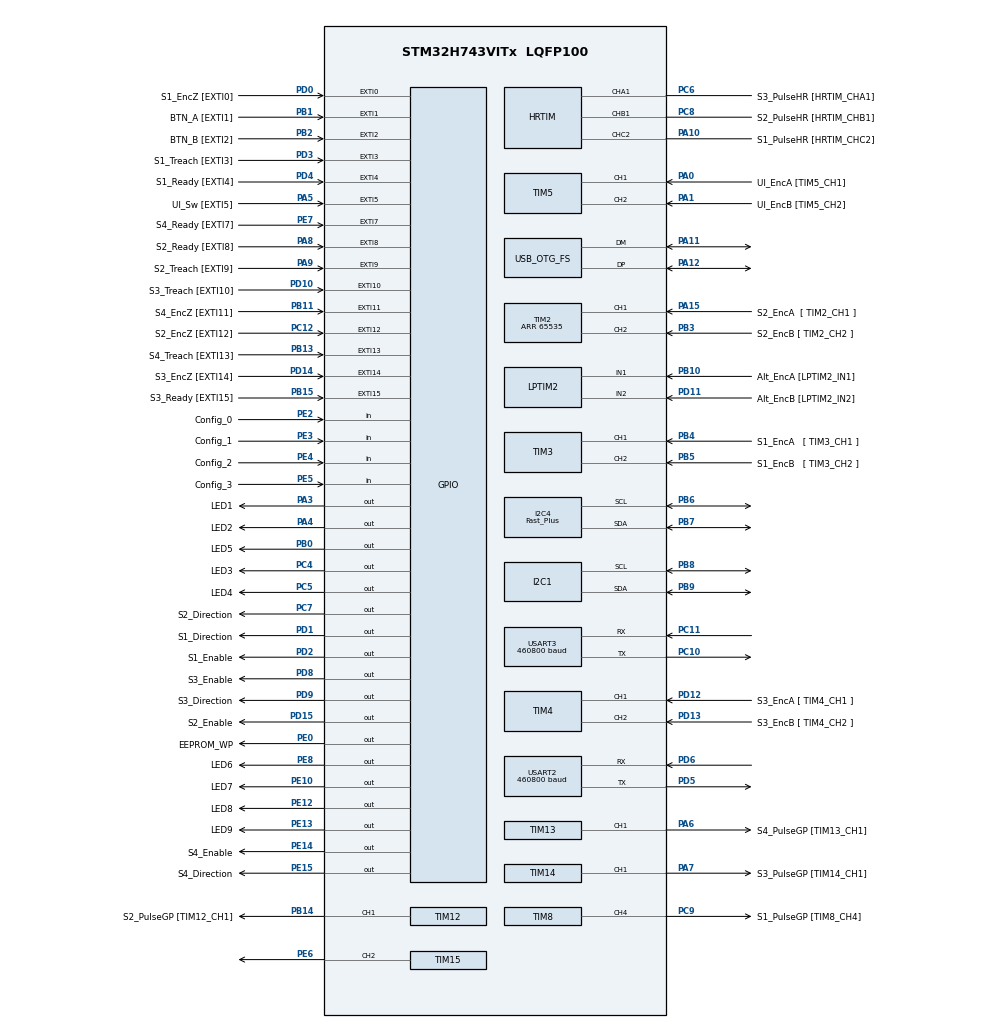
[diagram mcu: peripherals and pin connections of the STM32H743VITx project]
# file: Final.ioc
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CORTEX_M7.default_mode_Activation=1
Dma.Request0=USART2_TX
Dma.USART2_TX.0.Direction=DMA_MEMORY_TO_PERIPH
Dma.USART2_TX.0.EventEnable=DISABLE
Dma.USART2_TX.0.FIFOMode=DMA_FIFOMODE_DISABLE
Dma.USART2_TX.0.Instance=DMA1_Stream0
Dma.USART2_TX.0.MemDataAlignment=DMA_MDATAALIGN_BYTE
Dma.USART2_TX.0.MemInc=DMA_MINC_ENABLE
Dma.USART2_TX.0.Mode=DMA_NORMAL
Dma.USART2_TX.0.PeriphDataAlignment=DMA_PDATAALIGN_BYTE
Dma.USART2_TX.0.PeriphInc=DMA_PINC_DISABLE
Dma.USART2_TX.0.Polarity=HAL_DMAMUX_REQ_GEN_RISING
Dma.USART2_TX.0.Priority=DMA_PRIORITY_LOW
Dma.USART2_TX.0.RequestNumber=1
Dma.USART2_TX.0.SignalID=NONE
Dma.USART2_TX.0.SyncEnable=DISABLE
Dma.USART2_TX.0.SyncPolarity=HAL_DMAMUX_SYNC_NO_EVENT
Dma.USART2_TX.0.SyncRequestNumber=1
Dma.USART2_TX.0.SyncSignalID=NONE
I2C1.Timing=0x307075B1
I2C4.I2C_Speed_Mode=I2C_Fast_Plus
I2C4.Timing=0x0050174F
LPTIM2.ULPClockSampleTime=LPTIM_CLOCKSAMPLETIME_DIRECTTRANSITION
LPTIM2.UpdateMode=LPTIM_UPDATE_ENDOFPERIOD
Mcu.Family=STM32H7
Mcu.Name=STM32H743VITx
Mcu.Package=LQFP100
NVIC.DMA1_Stream0_IRQn=true\:0\:0\:false\:false\:true\:false\:true\:true
NVIC.EXTI0_IRQn=true\:1\:0\:true\:false\:true\:true\:true\:true
NVIC.EXTI15_10_IRQn=true\:1\:0\:true\:false\:true\:true\:true\:true
NVIC.EXTI1_IRQn=true\:1\:0\:true\:false\:true\:true\:true\:true
NVIC.EXTI2_IRQn=true\:1\:0\:true\:false\:true\:true\:true\:true
NVIC.EXTI3_IRQn=true\:1\:0\:true\:false\:true\:true\:true\:true
NVIC.EXTI4_IRQn=true\:1\:0\:true\:false\:true\:true\:true\:true
NVIC.EXTI9_5_IRQn=true\:1\:0\:true\:false\:true\:true\:true\:true
NVIC.OTG_FS_IRQn=true\:0\:0\:false\:false\:true\:false\:true\:true
NVIC.PriorityGroup=NVIC_PRIORITYGROUP_4
NVIC.TIM16_IRQn=true\:2\:0\:true\:false\:true\:true\:true\:true
NVIC.TIM17_IRQn=true\:1\:0\:true\:false\:true\:true\:true\:true
NVIC.USART2_IRQn=true\:0\:0\:true\:false\:true\:true\:true\:true
NVIC.USART3_IRQn=true\:1\:0\:true\:false\:true\:true\:true\:true
PA0.GPIO_Label=UI_EncA [TIM5_CH1]
PA0.Signal=S_TIM5_CH1
PA1.GPIO_Label=UI_EncB [TIM5_CH2]
PA1.Signal=S_TIM5_CH2
PA10.GPIO_Label=S1_PulseHR [HRTIM_CHC2]
PA10.Mode=Output_TC2
PA10.Signal=HRTIM_CHC2
PA11.Mode=Device_Only
PA11.Signal=USB_OTG_FS_DM
PA12.Mode=Device_Only
PA12.Signal=USB_OTG_FS_DP
PA13\ (JTMS/SWDIO).GPIO_Label=SWDIO
PA13\ (JTMS/SWDIO).Mode=Serial_Wire
PA13\ (JTMS/SWDIO).Signal=DEBUG_JTMS-SWDIO
PA14\ (JTCK/SWCLK).GPIO_Label=SWCLK
PA14\ (JTCK/SWCLK).Mode=Serial_Wire
PA14\ (JTCK/SWCLK).Signal=DEBUG_JTCK-SWCLK
PA15\ (JTDI).GPIO_Label=S2_EncA  [ TIM2_CH1 ]
PA15\ (JTDI).Signal=S_TIM2_CH1_ETR
PA3.GPIO_Label=LED1
PA3.Signal=GPIO_Output
PA4.GPIO_Label=LED2
PA4.Signal=GPIO_Output
PA5.GPIO_Label=UI_Sw [EXTI5]
PA5.Signal=GPXTI5
PA6.GPIO_Label=S4_PulseGP [TIM13_CH1]
PA6.Signal=S_TIM13_CH1
PA7.GPIO_Label=S3_PulseGP [TIM14_CH1]
PA7.Signal=S_TIM14_CH1
PA8.GPIO_Label=S2_Ready [EXTI8]
PA8.Signal=GPXTI8
PA9.GPIO_Label=S2_Treach [EXTI9]
PA9.GPIO_ModeDefaultEXTI=GPIO_MODE_IT_FALLING
PA9.Signal=GPXTI9
PB0.GPIO_Label=LED5
PB0.Signal=GPIO_Output
PB1.GPIO_Label=BTN_A [EXTI1]
PB1.Signal=GPXTI1
PB10.GPIO_Label=Alt_EncA [LPTIM2_IN1]
PB10.GPIO_PuPd=GPIO_PULLUP
PB10.Mode=Encoder_mode_occur1
PB10.Signal=LPTIM2_IN1
PB11.GPIO_Label=S4_EncZ [EXTI11]
PB11.Signal=GPXTI11
PB13.GPIO_Label=S4_Treach [EXTI13]
PB13.GPIO_ModeDefaultEXTI=GPIO_MODE_IT_FALLING
PB13.Signal=GPXTI13
PB14.GPIO_Label=S2_PulseGP [TIM12_CH1]
PB14.Signal=S_TIM12_CH1
PB15.GPIO_Label=S3_Ready [EXTI15]
PB15.Signal=GPXTI15
PB2.GPIO_Label=BTN_B [EXTI2]
PB2.Signal=GPXTI2
PB3\ (JTDO/TRACESWO).GPIO_Label=S2_EncB [ TIM2_CH2 ]
PB3\ (JTDO/TRACESWO).Signal=S_TIM2_CH2
PB4\ (NJTRST).GPIO_Label=S1_EncA   [ TIM3_CH1 ]
PB4\ (NJTRST).Signal=S_TIM3_CH1
PB5.GPIO_Label=S1_EncB   [ TIM3_CH2 ]
PB5.Signal=S_TIM3_CH2
PB6.GPIO_Pu=GPIO_NOPULL
PB6.GPIO_Speed=GPIO_SPEED_FREQ_LOW
PB6.Mode=I2C
PB6.Signal=I2C4_SCL
PB7.GPIO_Pu=GPIO_NOPULL
PB7.GPIO_Speed=GPIO_SPEED_FREQ_LOW
PB7.Mode=I2C
PB7.Signal=I2C4_SDA
PB8.Mode=I2C
PB8.Signal=I2C1_SCL
PB9.Mode=I2C
PB9.Signal=I2C1_SDA
PC10.Mode=Asynchronous
PC10.Signal=USART3_TX
PC11.Mode=Asynchronous
PC11.Signal=USART3_RX
PC12.GPIO_Label=S2_EncZ [EXTI12]
PC12.Signal=GPXTI12
PC4.GPIO_Label=LED3
PC4.Signal=GPIO_Output
PC5.GPIO_Label=LED4
PC5.Signal=GPIO_Output
PC6.GPIO_Label=S3_PulseHR [HRTIM_CHA1]
PC6.Mode=Output_TA1
PC6.Signal=HRTIM_CHA1
PC7.GPIO_Label=S2_Direction
PC7.Signal=GPIO_Output
PC8.GPIO_Label=S2_PulseHR [HRTIM_CHB1]
PC8.Mode=Output_TB1
PC8.Signal=HRTIM_CHB1
PC9.GPIO_Label=S1_PulseGP [TIM8_CH4]
PC9.Signal=S_TIM8_CH4
PD0.GPIO_Label=S1_EncZ [EXTI0]
PD0.Signal=GPXTI0
PD1.GPIO_Label=S1_Direction
PD1.Signal=GPIO_Output
PD10.GPIO_Label=S3_Treach [EXTI10]
PD10.GPIO_ModeDefaultEXTI=GPIO_MODE_IT_FALLING
PD10.Signal=GPXTI10
PD11.GPIO_Label=Alt_EncB [LPTIM2_IN2]
PD11.GPIO_PuPd=GPIO_PULLUP
PD11.Mode=Encoder_mode_occur1
PD11.Signal=LPTIM2_IN2
PD12.GPIO_Label=S3_EncA [ TIM4_CH1 ]
PD12.Signal=S_TIM4_CH1
PD13.GPIO_Label=S3_EncB [ TIM4_CH2 ]
PD13.Signal=S_TIM4_CH2
PD14.GPIO_Label=S3_EncZ [EXTI14]
PD14.Signal=GPXTI14
PD15.GPIO_Label=S2_Enable
PD15.Signal=GPIO_Output
PD2.GPIO_Label=S1_Enable
PD2.Signal=GPIO_Output
PD3.GPIO_Label=S1_Treach [EXTI3]
PD3.GPIO_ModeDefaultEXTI=GPIO_MODE_IT_FALLING
PD3.Signal=GPXTI3
PD4.GPIO_Label=S1_Ready [EXTI4]
PD4.Signal=GPXTI4
PD5.Mode=Asynchronous
PD5.Signal=USART2_TX
PD6.Mode=Asynchronous
PD6.Signal=USART2_RX
PD8.GPIO_Label=S3_Enable
PD8.Signal=GPIO_Output
PD9.GPIO_Label=S3_Direction
PD9.Signal=GPIO_Output
PE0.GPIO_Label=EEPROM_WP
PE0.Signal=GPIO_Output
PE10.GPIO_Label=LED7
PE10.Signal=GPIO_Output
PE11.GPIO_Label=S4_EncB  [TIM1_CH2]
PE11.Signal=S_TIM1_CH2
PE12.GPIO_Label=LED8
PE12.Signal=GPIO_Output
PE13.GPIO_Label=LED9
PE13.Signal=GPIO_Output
PE14.GPIO_Label=S4_Enable
PE14.Signal=GPIO_Output
PE15.GPIO_Label=S4_Direction
PE15.Signal=GPIO_Output
PE2.GPIO_Label=Config_0
PE2.Signal=GPIO_Input
PE3.GPIO_Label=Config_1
PE3.Signal=GPIO_Input
PE4.GPIO_Label=Config_2
PE4.Signal=GPIO_Input
PE5.GPIO_Label=Config_3
PE5.Signal=GPIO_Input
PE6.Signal=S_TIM15_CH2
PE7.GPIO_Label=S4_Ready [EXTI7]
PE7.Signal=GPXTI7
PE8.GPIO_Label=LED6
PE8.Signal=GPIO_Output
PE9.GPIO_Label=S4_EncA  [TIM1_CH1]
PE9.Signal=S_TIM1_CH1
PH0-OSC_IN\ (PH0).Mode=HSE-External-Oscillator
PH0-OSC_IN\ (PH0).Signal=RCC_OSC_IN
PH1-OSC_OUT\ (PH1).Mode=HSE-External-Oscillator
PH1-OSC_OUT\ (PH1).Signal=RCC_OSC_OUT
ProjectManager.HeapSize=0x200
ProjectManager.StackSize=0x400
ProjectManager.TargetToolchain=STM32CubeIDE
RCC.ADCFreq_Value=16125000
RCC.APB1Freq_Value=120000000
RCC.APB2Freq_Value=120000000
RCC.APB3Freq_Value=120000000
RCC.APB4Freq_Value=120000000
RCC.CortexFreq_Value=480000000
RCC.D1PPRE=RCC_APB3_DIV2
RCC.D2PPRE1=RCC_APB1_DIV2
RCC.D2PPRE2=RCC_APB2_DIV2
RCC.D3PPRE=RCC_APB4_DIV2
RCC.DIVM1=1
RCC.DIVN1=120
RCC.DIVQ1=15
RCC.HCLKFreq_Value=240000000
RCC.HPRE=RCC_HCLK_DIV2
RCC.HSE_VALUE=8000000
RCC.PLL2FRACN=0
RCC.PLL3FRACN=0
RCC.PLLFRACN=0
RCC.SYSCLKFreq_VALUE=480000000
RCC.SYSCLKSource=RCC_SYSCLKSOURCE_PLLCLK
RCC.USBFreq_Value=64000000
SH.S_TIM12_CH1.0=TIM12_CH1,Output Compare1 CH1
SH.S_TIM13_CH1.0=TIM13_CH1,Output Compare1 CH1
SH.S_TIM14_CH1.0=TIM14_CH1,Output Compare1 CH1
SH.S_TIM15_CH2.0=TIM15_CH2,Output Compare2 CH2
SH.S_TIM1_CH1.0=TIM1_CH1
SH.S_TIM1_CH2.0=TIM1_CH2
SH.S_TIM2_CH1_ETR.0=TIM2_CH1,Encoder_Interface
SH.S_TIM2_CH2.0=TIM2_CH2,Encoder_Interface
SH.S_TIM3_CH1.0=TIM3_CH1,Encoder_Interface
SH.S_TIM3_CH2.0=TIM3_CH2,Encoder_Interface
SH.S_TIM4_CH1.0=TIM4_CH1,Encoder_Interface
SH.S_TIM4_CH2.0=TIM4_CH2,Encoder_Interface
SH.S_TIM5_CH1.0=TIM5_CH1,Encoder_Interface
SH.S_TIM5_CH2.0=TIM5_CH2,Encoder_Interface
SH.S_TIM8_CH4.0=TIM8_CH4,Output Compare4 CH4
TIM12.Channel-Output\ Compare1\ CH1=TIM_CHANNEL_1
TIM12.OCMode_1=TIM_OCMODE_TOGGLE
TIM12.Prescaler=5
TIM13.Channel=TIM_CHANNEL_1
TIM13.OCMode_1=TIM_OCMODE_TOGGLE
TIM13.Prescaler=5
TIM14.Channel=TIM_CHANNEL_1
TIM14.OCMode_1=TIM_OCMODE_TOGGLE
TIM14.Prescaler=5
TIM15.Channel-Output\ Compare2\ CH2=TIM_CHANNEL_2
TIM15.OCMode_2=TIM_OCMODE_TOGGLE
TIM15.Prescaler=5
TIM15.TIM_MasterOutputTrigger=TIM_TRGO_OC2REF
TIM16.Prescaler=11999
TIM17.Period=999
TIM17.Prescaler=239
TIM2.EncoderMode=TIM_ENCODERMODE_TI12
TIM2.Period=65535
TIM3.EncoderMode=TIM_ENCODERMODE_TI12
TIM4.EncoderMode=TIM_ENCODERMODE_TI12
TIM5.EncoderMode=TIM_ENCODERMODE_TI1
TIM8.Channel-Output\ Compare4\ CH4=TIM_CHANNEL_4
TIM8.OCMode_4=TIM_OCMODE_TOGGLE
TIM8.Prescaler=5
TIM8.TIM_MasterOutputTrigger=TIM_TRGO_OC4REF
USART2.BaudRate=460800
USART2.VirtualMode-Asynchronous=VM_ASYNC
USART3.BaudRate=460800
USART3.VirtualMode-Asynchronous=VM_ASYNC
USB_DEVICE.CLASS_NAME_FS=CDC
USB_DEVICE.VirtualMode-CDC_FS=Cdc
USB_DEVICE.VirtualModeFS=Cdc_FS
USB_OTG_FS.VirtualMode=Device_Only
VP_MEMORYMAP_VS_MEMORYMAP.Mode=CurAppReg
VP_TIM12_VS_ClockSourceINT.Mode=Internal
VP_TIM13_VS_ClockSourceINT.Mode=Enable_Timer
VP_TIM14_VS_ClockSourceINT.Mode=Enable_Timer
VP_TIM15_VS_ClockSourceINT.Mode=Internal
VP_TIM16_VS_ClockSourceINT.Mode=Enable_Timer
VP_TIM17_VS_ClockSourceINT.Mode=Enable_Timer
VP_TIM1_VS_ClockSourceITR.Mode=TriggerSource_ITR0
VP_TIM1_VS_ControllerModeClock.Mode=Clock Mode
VP_TIM8_VS_ClockSourceINT.Mode=Internal
VP_USB_DEVICE_VS_USB_DEVICE_CDC_FS.Mode=CDC_FS
board=custom

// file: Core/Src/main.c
/* USER CODE BEGIN Header */
/**
  ******************************************************************************
  * @file           : main.c
  * @brief          : Main program body
  ******************************************************************************
  * @attention
  *
  * Copyright (c) 2025 STMicroelectronics.
  * All rights reserved.
  *
  * This software is licensed under terms that can be found in the LICENSE file
  * in the root directory of this software component.
  * If no LICENSE file comes with this software, it is provided AS-IS.
  *
  ******************************************************************************
  */
/* USER CODE END Header */
#include "main.h"
#include "usb_device.h"

/* USER CODE BEGIN Includes */
#include <customMain.h>
/* USER CODE END Includes */

HRTIM_HandleTypeDef hhrtim;

I2C_HandleTypeDef hi2c1;
I2C_HandleTypeDef hi2c4;

LPTIM_HandleTypeDef hlptim2;

TIM_HandleTypeDef htim1;
TIM_HandleTypeDef htim2;
TIM_HandleTypeDef htim3;
TIM_HandleTypeDef htim4;
TIM_HandleTypeDef htim5;
TIM_HandleTypeDef htim8;
TIM_HandleTypeDef htim12;
TIM_HandleTypeDef htim13;
TIM_HandleTypeDef htim14;
TIM_HandleTypeDef htim15;
TIM_HandleTypeDef htim16;
TIM_HandleTypeDef htim17;

UART_HandleTypeDef huart2;
UART_HandleTypeDef huart3;
DMA_HandleTypeDef hdma_usart2_tx;

void SystemClock_Config(void);
static void MPU_Config(void);
static void MX_GPIO_Init(void);
static void MX_DMA_Init(void);
static void MX_HRTIM_Init(void);
static void MX_I2C1_Init(void);
static void MX_I2C4_Init(void);
static void MX_LPTIM2_Init(void);
static void MX_TIM1_Init(void);
static void MX_TIM2_Init(void);
static void MX_TIM3_Init(void);
static void MX_TIM4_Init(void);
static void MX_TIM5_Init(void);
static void MX_TIM8_Init(void);
static void MX_TIM12_Init(void);
static void MX_TIM13_Init(void);
static void MX_TIM14_Init(void);
static void MX_TIM16_Init(void);
static void MX_TIM17_Init(void);
static void MX_USART2_UART_Init(void);
static void MX_USART3_UART_Init(void);
static void MX_TIM15_Init(void);

int main(void)
{

  /* MPU Configuration--------------------------------------------------------*/
  MPU_Config();

  /* MCU Configuration--------------------------------------------------------*/

  /* Reset of all peripherals, Initializes the Flash interface and the Systick. */
  HAL_Init();

  /* Configure the system clock */
  SystemClock_Config();

  /* Initialize all configured peripherals */
  MX_GPIO_Init();
  MX_DMA_Init();
  MX_HRTIM_Init();
  MX_I2C1_Init();
  MX_I2C4_Init();
  MX_LPTIM2_Init();
  MX_TIM1_Init();
  MX_TIM2_Init();
  MX_TIM3_Init();
  MX_TIM4_Init();
  MX_TIM5_Init();
  MX_TIM8_Init();
  MX_TIM12_Init();
  MX_TIM13_Init();
  MX_TIM14_Init();
  MX_TIM16_Init();
  MX_TIM17_Init();
  MX_USART2_UART_Init();
  MX_USART3_UART_Init();
  MX_USB_DEVICE_Init();
  MX_TIM15_Init();
  /* USER CODE BEGIN 2 */
  userInit();
  /* USER CODE END 2 */

  /* Infinite loop */
  while (1)
  {

    /* USER CODE BEGIN 3 */
	  userLoop();
  }
  /* USER CODE END 3 */
}

void SystemClock_Config(void)
{
  RCC_OscInitTypeDef RCC_OscInitStruct = {0};
  RCC_ClkInitTypeDef RCC_ClkInitStruct = {0};

  /** Supply configuration update enable
  */
  HAL_PWREx_ConfigSupply(PWR_LDO_SUPPLY);

  /** Configure the main internal regulator output voltage
  */
  __HAL_PWR_VOLTAGESCALING_CONFIG(PWR_REGULATOR_VOLTAGE_SCALE0);

  while(!__HAL_PWR_GET_FLAG(PWR_FLAG_VOSRDY)) {}

  /** Initializes the RCC Oscillators according to the specified parameters
  * in the RCC_OscInitTypeDef structure.
  */
  RCC_OscInitStruct.OscillatorType = RCC_OSCILLATORTYPE_HSE;
  RCC_OscInitStruct.HSEState = RCC_HSE_ON;
  RCC_OscInitStruct.PLL.PLLState = RCC_PLL_ON;
  RCC_OscInitStruct.PLL.PLLSource = RCC_PLLSOURCE_HSE;
  RCC_OscInitStruct.PLL.PLLM = 1;
  RCC_OscInitStruct.PLL.PLLN = 120;
  RCC_OscInitStruct.PLL.PLLP = 2;
  RCC_OscInitStruct.PLL.PLLQ = 15;
  RCC_OscInitStruct.PLL.PLLR = 2;
  RCC_OscInitStruct.PLL.PLLRGE = RCC_PLL1VCIRANGE_3;
  RCC_OscInitStruct.PLL.PLLVCOSEL = RCC_PLL1VCOWIDE;
  RCC_OscInitStruct.PLL.PLLFRACN = 0;
  if (HAL_RCC_OscConfig(&RCC_OscInitStruct) != HAL_OK)
  {
    Error_Handler();
  }

  /** Initializes the CPU, AHB and APB buses clocks
  */
  RCC_ClkInitStruct.ClockType = RCC_CLOCKTYPE_HCLK|RCC_CLOCKTYPE_SYSCLK
                              |RCC_CLOCKTYPE_PCLK1|RCC_CLOCKTYPE_PCLK2
                              |RCC_CLOCKTYPE_D3PCLK1|RCC_CLOCKTYPE_D1PCLK1;
  RCC_ClkInitStruct.SYSCLKSource = RCC_SYSCLKSOURCE_PLLCLK;
  RCC_ClkInitStruct.SYSCLKDivider = RCC_SYSCLK_DIV1;
  RCC_ClkInitStruct.AHBCLKDivider = RCC_HCLK_DIV2;
  RCC_ClkInitStruct.APB3CLKDivider = RCC_APB3_DIV2;
  RCC_ClkInitStruct.APB1CLKDivider = RCC_APB1_DIV2;
  RCC_ClkInitStruct.APB2CLKDivider = RCC_APB2_DIV2;
  RCC_ClkInitStruct.APB4CLKDivider = RCC_APB4_DIV2;

  if (HAL_RCC_ClockConfig(&RCC_ClkInitStruct, FLASH_LATENCY_4) != HAL_OK)
  {
    Error_Handler();
  }
}

static void MX_HRTIM_Init(void)
{

  HRTIM_TimeBaseCfgTypeDef pTimeBaseCfg = {0};
  HRTIM_TimerCfgTypeDef pTimerCfg = {0};
  HRTIM_OutputCfgTypeDef pOutputCfg = {0};

  hhrtim.Instance = HRTIM1;
  hhrtim.Init.HRTIMInterruptResquests = HRTIM_IT_NONE;
  hhrtim.Init.SyncOptions = HRTIM_SYNCOPTION_NONE;
  if (HAL_HRTIM_Init(&hhrtim) != HAL_OK)
  {
    Error_Handler();
  }
  pTimeBaseCfg.Period = 0xFFFD;
  pTimeBaseCfg.RepetitionCounter = 0x00;
  pTimeBaseCfg.PrescalerRatio = HRTIM_PRESCALERRATIO_DIV1;
  pTimeBaseCfg.Mode = HRTIM_MODE_CONTINUOUS;
  if (HAL_HRTIM_TimeBaseConfig(&hhrtim, HRTIM_TIMERINDEX_TIMER_A, &pTimeBaseCfg) != HAL_OK)
  {
    Error_Handler();
  }
  pTimerCfg.InterruptRequests = HRTIM_TIM_IT_NONE;
  pTimerCfg.DMARequests = HRTIM_TIM_DMA_NONE;
  pTimerCfg.DMASrcAddress = 0x0000;
  pTimerCfg.DMADstAddress = 0x0000;
  pTimerCfg.DMASize = 0x1;
  pTimerCfg.HalfModeEnable = HRTIM_HALFMODE_DISABLED;
  pTimerCfg.StartOnSync = HRTIM_SYNCSTART_DISABLED;
  pTimerCfg.ResetOnSync = HRTIM_SYNCRESET_DISABLED;
  pTimerCfg.DACSynchro = HRTIM_DACSYNC_NONE;
  pTimerCfg.PreloadEnable = HRTIM_PRELOAD_DISABLED;
  pTimerCfg.UpdateGating = HRTIM_UPDATEGATING_INDEPENDENT;
  pTimerCfg.BurstMode = HRTIM_TIMERBURSTMODE_MAINTAINCLOCK;
  pTimerCfg.RepetitionUpdate = HRTIM_UPDATEONREPETITION_DISABLED;
  pTimerCfg.PushPull = HRTIM_TIMPUSHPULLMODE_DISABLED;
  pTimerCfg.FaultEnable = HRTIM_TIMFAULTENABLE_NONE;
  pTimerCfg.FaultLock = HRTIM_TIMFAULTLOCK_READWRITE;
  pTimerCfg.DeadTimeInsertion = HRTIM_TIMDEADTIMEINSERTION_DISABLED;
  pTimerCfg.DelayedProtectionMode = HRTIM_TIMER_A_B_C_DELAYEDPROTECTION_DISABLED;
  pTimerCfg.UpdateTrigger = HRTIM_TIMUPDATETRIGGER_NONE;
  pTimerCfg.ResetTrigger = HRTIM_TIMRESETTRIGGER_NONE;
  pTimerCfg.ResetUpdate = HRTIM_TIMUPDATEONRESET_DISABLED;
  if (HAL_HRTIM_WaveformTimerConfig(&hhrtim, HRTIM_TIMERINDEX_TIMER_A, &pTimerCfg) != HAL_OK)
  {
    Error_Handler();
  }
  if (HAL_HRTIM_WaveformTimerConfig(&hhrtim, HRTIM_TIMERINDEX_TIMER_B, &pTimerCfg) != HAL_OK)
  {
    Error_Handler();
  }
  if (HAL_HRTIM_WaveformTimerConfig(&hhrtim, HRTIM_TIMERINDEX_TIMER_C, &pTimerCfg) != HAL_OK)
  {
    Error_Handler();
  }
  pOutputCfg.Polarity = HRTIM_OUTPUTPOLARITY_HIGH;
  pOutputCfg.SetSource = HRTIM_OUTPUTSET_NONE;
  pOutputCfg.ResetSource = HRTIM_OUTPUTRESET_NONE;
  pOutputCfg.IdleMode = HRTIM_OUTPUTIDLEMODE_NONE;
  pOutputCfg.IdleLevel = HRTIM_OUTPUTIDLELEVEL_INACTIVE;
  pOutputCfg.FaultLevel = HRTIM_OUTPUTFAULTLEVEL_NONE;
  pOutputCfg.ChopperModeEnable = HRTIM_OUTPUTCHOPPERMODE_DISABLED;
  pOutputCfg.BurstModeEntryDelayed = HRTIM_OUTPUTBURSTMODEENTRY_REGULAR;
  if (HAL_HRTIM_WaveformOutputConfig(&hhrtim, HRTIM_TIMERINDEX_TIMER_A, HRTIM_OUTPUT_TA1, &pOutputCfg) != HAL_OK)
  {
    Error_Handler();
  }
  if (HAL_HRTIM_WaveformOutputConfig(&hhrtim, HRTIM_TIMERINDEX_TIMER_B, HRTIM_OUTPUT_TB1, &pOutputCfg) != HAL_OK)
  {
    Error_Handler();
  }
  if (HAL_HRTIM_TimeBaseConfig(&hhrtim, HRTIM_TIMERINDEX_TIMER_B, &pTimeBaseCfg) != HAL_OK)
  {
    Error_Handler();
  }
  if (HAL_HRTIM_TimeBaseConfig(&hhrtim, HRTIM_TIMERINDEX_TIMER_C, &pTimeBaseCfg) != HAL_OK)
  {
    Error_Handler();
  }
  if (HAL_HRTIM_WaveformOutputConfig(&hhrtim, HRTIM_TIMERINDEX_TIMER_C, HRTIM_OUTPUT_TC2, &pOutputCfg) != HAL_OK)
  {
    Error_Handler();
  }
  HAL_HRTIM_MspPostInit(&hhrtim);

}

static void MX_I2C1_Init(void)
{

  hi2c1.Instance = I2C1;
  hi2c1.Init.Timing = 0x307075B1;
  hi2c1.Init.OwnAddress1 = 0;
  hi2c1.Init.AddressingMode = I2C_ADDRESSINGMODE_7BIT;
  hi2c1.Init.DualAddressMode = I2C_DUALADDRESS_DISABLE;
  hi2c1.Init.OwnAddress2 = 0;
  hi2c1.Init.OwnAddress2Masks = I2C_OA2_NOMASK;
  hi2c1.Init.GeneralCallMode = I2C_GENERALCALL_DISABLE;
  hi2c1.Init.NoStretchMode = I2C_NOSTRETCH_DISABLE;
  if (HAL_I2C_Init(&hi2c1) != HAL_OK)
  {
    Error_Handler();
  }

  /** Configure Analogue filter
  */
  if (HAL_I2CEx_ConfigAnalogFilter(&hi2c1, I2C_ANALOGFILTER_ENABLE) != HAL_OK)
  {
    Error_Handler();
  }

  /** Configure Digital filter
  */
  if (HAL_I2CEx_ConfigDigitalFilter(&hi2c1, 0) != HAL_OK)
  {
    Error_Handler();
  }

}

static void MX_I2C4_Init(void)
{

  hi2c4.Instance = I2C4;
  hi2c4.Init.Timing = 0x0050174F;
  hi2c4.Init.OwnAddress1 = 0;
  hi2c4.Init.AddressingMode = I2C_ADDRESSINGMODE_7BIT;
  hi2c4.Init.DualAddressMode = I2C_DUALADDRESS_DISABLE;
  hi2c4.Init.OwnAddress2 = 0;
  hi2c4.Init.OwnAddress2Masks = I2C_OA2_NOMASK;
  hi2c4.Init.GeneralCallMode = I2C_GENERALCALL_DISABLE;
  hi2c4.Init.NoStretchMode = I2C_NOSTRETCH_DISABLE;
  if (HAL_I2C_Init(&hi2c4) != HAL_OK)
  {
    Error_Handler();
  }

  /** Configure Analogue filter
  */
  if (HAL_I2CEx_ConfigAnalogFilter(&hi2c4, I2C_ANALOGFILTER_ENABLE) != HAL_OK)
  {
    Error_Handler();
  }

  /** Configure Digital filter
  */
  if (HAL_I2CEx_ConfigDigitalFilter(&hi2c4, 0) != HAL_OK)
  {
    Error_Handler();
  }

  /** I2C Enable Fast Mode Plus
  */
  HAL_I2CEx_EnableFastModePlus(I2C_FASTMODEPLUS_I2C4);

}

static void MX_LPTIM2_Init(void)
{

  hlptim2.Instance = LPTIM2;
  hlptim2.Init.Clock.Source = LPTIM_CLOCKSOURCE_APBCLOCK_LPOSC;
  hlptim2.Init.Clock.Prescaler = LPTIM_PRESCALER_DIV1;
  hlptim2.Init.UltraLowPowerClock.Polarity = LPTIM_CLOCKPOLARITY_RISING;
  hlptim2.Init.UltraLowPowerClock.SampleTime = LPTIM_CLOCKSAMPLETIME_DIRECTTRANSITION;
  hlptim2.Init.Trigger.Source = LPTIM_TRIGSOURCE_SOFTWARE;
  hlptim2.Init.OutputPolarity = LPTIM_OUTPUTPOLARITY_HIGH;
  hlptim2.Init.UpdateMode = LPTIM_UPDATE_ENDOFPERIOD;
  hlptim2.Init.CounterSource = LPTIM_COUNTERSOURCE_EXTERNAL;
  hlptim2.Init.Input1Source = LPTIM_INPUT1SOURCE_GPIO;
  hlptim2.Init.Input2Source = LPTIM_INPUT2SOURCE_GPIO;
  if (HAL_LPTIM_Init(&hlptim2) != HAL_OK)
  {
    Error_Handler();
  }

}

static void MX_TIM1_Init(void)
{

  TIM_SlaveConfigTypeDef sSlaveConfig = {0};
  TIM_MasterConfigTypeDef sMasterConfig = {0};

  htim1.Instance = TIM1;
  htim1.Init.Prescaler = 0;
  htim1.Init.CounterMode = TIM_COUNTERMODE_UP;
  htim1.Init.Period = 65535;
  htim1.Init.ClockDivision = TIM_CLOCKDIVISION_DIV1;
  htim1.Init.RepetitionCounter = 0;
  htim1.Init.AutoReloadPreload = TIM_AUTORELOAD_PRELOAD_DISABLE;
  if (HAL_TIM_Base_Init(&htim1) != HAL_OK)
  {
    Error_Handler();
  }
  sSlaveConfig.SlaveMode = TIM_SLAVEMODE_EXTERNAL1;
  sSlaveConfig.InputTrigger = TIM_TS_ITR0;
  if (HAL_TIM_SlaveConfigSynchro(&htim1, &sSlaveConfig) != HAL_OK)
  {
    Error_Handler();
  }
  sMasterConfig.MasterOutputTrigger = TIM_TRGO_RESET;
  sMasterConfig.MasterOutputTrigger2 = TIM_TRGO2_RESET;
  sMasterConfig.MasterSlaveMode = TIM_MASTERSLAVEMODE_DISABLE;
  if (HAL_TIMEx_MasterConfigSynchronization(&htim1, &sMasterConfig) != HAL_OK)
  {
    Error_Handler();
  }

}

static void MX_TIM2_Init(void)
{

  TIM_Encoder_InitTypeDef sConfig = {0};
  TIM_MasterConfigTypeDef sMasterConfig = {0};

  htim2.Instance = TIM2;
  htim2.Init.Prescaler = 0;
  htim2.Init.CounterMode = TIM_COUNTERMODE_UP;
  htim2.Init.Period = 65535;
  htim2.Init.ClockDivision = TIM_CLOCKDIVISION_DIV1;
  htim2.Init.AutoReloadPreload = TIM_AUTORELOAD_PRELOAD_DISABLE;
  sConfig.EncoderMode = TIM_ENCODERMODE_TI12;
  sConfig.IC1Polarity = TIM_ICPOLARITY_RISING;
  sConfig.IC1Selection = TIM_ICSELECTION_DIRECTTI;
  sConfig.IC1Prescaler = TIM_ICPSC_DIV1;
  sConfig.IC1Filter = 0;
  sConfig.IC2Polarity = TIM_ICPOLARITY_RISING;
  sConfig.IC2Selection = TIM_ICSELECTION_DIRECTTI;
  sConfig.IC2Prescaler = TIM_ICPSC_DIV1;
  sConfig.IC2Filter = 0;
  if (HAL_TIM_Encoder_Init(&htim2, &sConfig) != HAL_OK)
  {
    Error_Handler();
  }
  sMasterConfig.MasterOutputTrigger = TIM_TRGO_RESET;
  sMasterConfig.MasterSlaveMode = TIM_MASTERSLAVEMODE_DISABLE;
  if (HAL_TIMEx_MasterConfigSynchronization(&htim2, &sMasterConfig) != HAL_OK)
  {
    Error_Handler();
  }

}

static void MX_TIM3_Init(void)
{

  TIM_Encoder_InitTypeDef sConfig = {0};
  TIM_MasterConfigTypeDef sMasterConfig = {0};

  htim3.Instance = TIM3;
  htim3.Init.Prescaler = 0;
  htim3.Init.CounterMode = TIM_COUNTERMODE_UP;
  htim3.Init.Period = 65535;
  htim3.Init.ClockDivision = TIM_CLOCKDIVISION_DIV1;
  htim3.Init.AutoReloadPreload = TIM_AUTORELOAD_PRELOAD_DISABLE;
  sConfig.EncoderMode = TIM_ENCODERMODE_TI12;
  sConfig.IC1Polarity = TIM_ICPOLARITY_RISING;
  sConfig.IC1Selection = TIM_ICSELECTION_DIRECTTI;
  sConfig.IC1Prescaler = TIM_ICPSC_DIV1;
  sConfig.IC1Filter = 0;
  sConfig.IC2Polarity = TIM_ICPOLARITY_RISING;
  sConfig.IC2Selection = TIM_ICSELECTION_DIRECTTI;
  sConfig.IC2Prescaler = TIM_ICPSC_DIV1;
  sConfig.IC2Filter = 0;
  if (HAL_TIM_Encoder_Init(&htim3, &sConfig) != HAL_OK)
  {
    Error_Handler();
  }
  sMasterConfig.MasterOutputTrigger = TIM_TRGO_RESET;
  sMasterConfig.MasterSlaveMode = TIM_MASTERSLAVEMODE_DISABLE;
  if (HAL_TIMEx_MasterConfigSynchronization(&htim3, &sMasterConfig) != HAL_OK)
  {
    Error_Handler();
  }

}

static void MX_TIM4_Init(void)
{

  TIM_Encoder_InitTypeDef sConfig = {0};
  TIM_MasterConfigTypeDef sMasterConfig = {0};

  htim4.Instance = TIM4;
  htim4.Init.Prescaler = 0;
  htim4.Init.CounterMode = TIM_COUNTERMODE_UP;
  htim4.Init.Period = 65535;
  htim4.Init.ClockDivision = TIM_CLOCKDIVISION_DIV1;
  htim4.Init.AutoReloadPreload = TIM_AUTORELOAD_PRELOAD_DISABLE;
  sConfig.EncoderMode = TIM_ENCODERMODE_TI12;
  sConfig.IC1Polarity = TIM_ICPOLARITY_RISING;
  sConfig.IC1Selection = TIM_ICSELECTION_DIRECTTI;
  sConfig.IC1Prescaler = TIM_ICPSC_DIV1;
  sConfig.IC1Filter = 0;
  sConfig.IC2Polarity = TIM_ICPOLARITY_RISING;
  sConfig.IC2Selection = TIM_ICSELECTION_DIRECTTI;
  sConfig.IC2Prescaler = TIM_ICPSC_DIV1;
  sConfig.IC2Filter = 0;
  if (HAL_TIM_Encoder_Init(&htim4, &sConfig) != HAL_OK)
  {
    Error_Handler();
  }
  sMasterConfig.MasterOutputTrigger = TIM_TRGO_RESET;
  sMasterConfig.MasterSlaveMode = TIM_MASTERSLAVEMODE_DISABLE;
  if (HAL_TIMEx_MasterConfigSynchronization(&htim4, &sMasterConfig) != HAL_OK)
  {
    Error_Handler();
  }

}

static void MX_TIM5_Init(void)
{

  TIM_Encoder_InitTypeDef sConfig = {0};
  TIM_MasterConfigTypeDef sMasterConfig = {0};

  htim5.Instance = TIM5;
  htim5.Init.Prescaler = 0;
  htim5.Init.CounterMode = TIM_COUNTERMODE_UP;
  htim5.Init.Period = 4294967295;
  htim5.Init.ClockDivision = TIM_CLOCKDIVISION_DIV1;
  htim5.Init.AutoReloadPreload = TIM_AUTORELOAD_PRELOAD_DISABLE;
  sConfig.EncoderMode = TIM_ENCODERMODE_TI1;
  sConfig.IC1Polarity = TIM_ICPOLARITY_RISING;
  sConfig.IC1Selection = TIM_ICSELECTION_DIRECTTI;
  sConfig.IC1Prescaler = TIM_ICPSC_DIV1;
  sConfig.IC1Filter = 0;
  sConfig.IC2Polarity = TIM_ICPOLARITY_RISING;
  sConfig.IC2Selection = TIM_ICSELECTION_DIRECTTI;
  sConfig.IC2Prescaler = TIM_ICPSC_DIV1;
  sConfig.IC2Filter = 0;
  if (HAL_TIM_Encoder_Init(&htim5, &sConfig) != HAL_OK)
  {
    Error_Handler();
  }
  sMasterConfig.MasterOutputTrigger = TIM_TRGO_RESET;
  sMasterConfig.MasterSlaveMode = TIM_MASTERSLAVEMODE_DISABLE;
  if (HAL_TIMEx_MasterConfigSynchronization(&htim5, &sMasterConfig) != HAL_OK)
  {
    Error_Handler();
  }

}

static void MX_TIM8_Init(void)
{

  TIM_ClockConfigTypeDef sClockSourceConfig = {0};
  TIM_MasterConfigTypeDef sMasterConfig = {0};
  TIM_OC_InitTypeDef sConfigOC = {0};
  TIM_BreakDeadTimeConfigTypeDef sBreakDeadTimeConfig = {0};

  htim8.Instance = TIM8;
  htim8.Init.Prescaler = 5;
  htim8.Init.CounterMode = TIM_COUNTERMODE_UP;
  htim8.Init.Period = 65535;
  htim8.Init.ClockDivision = TIM_CLOCKDIVISION_DIV1;
  htim8.Init.RepetitionCounter = 0;
  htim8.Init.AutoReloadPreload = TIM_AUTORELOAD_PRELOAD_DISABLE;
  if (HAL_TIM_Base_Init(&htim8) != HAL_OK)
  {
    Error_Handler();
  }
  sClockSourceConfig.ClockSource = TIM_CLOCKSOURCE_INTERNAL;
  if (HAL_TIM_ConfigClockSource(&htim8, &sClockSourceConfig) != HAL_OK)
  {
    Error_Handler();
  }
  if (HAL_TIM_OC_Init(&htim8) != HAL_OK)
  {
    Error_Handler();
  }
  sMasterConfig.MasterOutputTrigger = TIM_TRGO_OC4REF;
  sMasterConfig.MasterOutputTrigger2 = TIM_TRGO2_RESET;
  sMasterConfig.MasterSlaveMode = TIM_MASTERSLAVEMODE_DISABLE;
  if (HAL_TIMEx_MasterConfigSynchronization(&htim8, &sMasterConfig) != HAL_OK)
  {
    Error_Handler();
  }
  sConfigOC.OCMode = TIM_OCMODE_TOGGLE;
  sConfigOC.Pulse = 0;
  sConfigOC.OCPolarity = TIM_OCPOLARITY_HIGH;
  sConfigOC.OCFastMode = TIM_OCFAST_DISABLE;
  sConfigOC.OCIdleState = TIM_OCIDLESTATE_RESET;
  sConfigOC.OCNIdleState = TIM_OCNIDLESTATE_RESET;
  if (HAL_TIM_OC_ConfigChannel(&htim8, &sConfigOC, TIM_CHANNEL_4) != HAL_OK)
  {
    Error_Handler();
  }
  sBreakDeadTimeConfig.OffStateRunMode = TIM_OSSR_DISABLE;
  sBreakDeadTimeConfig.OffStateIDLEMode = TIM_OSSI_DISABLE;
  sBreakDeadTimeConfig.LockLevel = TIM_LOCKLEVEL_OFF;
  sBreakDeadTimeConfig.DeadTime = 0;
  sBreakDeadTimeConfig.BreakState = TIM_BREAK_DISABLE;
  sBreakDeadTimeConfig.BreakPolarity = TIM_BREAKPOLARITY_HIGH;
  sBreakDeadTimeConfig.BreakFilter = 0;
  sBreakDeadTimeConfig.Break2State = TIM_BREAK2_DISABLE;
  sBreakDeadTimeConfig.Break2Polarity = TIM_BREAK2POLARITY_HIGH;
  sBreakDeadTimeConfig.Break2Filter = 0;
  sBreakDeadTimeConfig.AutomaticOutput = TIM_AUTOMATICOUTPUT_DISABLE;
  if (HAL_TIMEx_ConfigBreakDeadTime(&htim8, &sBreakDeadTimeConfig) != HAL_OK)
  {
    Error_Handler();
  }
  HAL_TIM_MspPostInit(&htim8);

}

static void MX_TIM12_Init(void)
{

  TIM_ClockConfigTypeDef sClockSourceConfig = {0};
  TIM_MasterConfigTypeDef sMasterConfig = {0};
  TIM_OC_InitTypeDef sConfigOC = {0};

  htim12.Instance = TIM12;
  htim12.Init.Prescaler = 5;
  htim12.Init.CounterMode = TIM_COUNTERMODE_UP;
  htim12.Init.Period = 65535;
  htim12.Init.ClockDivision = TIM_CLOCKDIVISION_DIV1;
  htim12.Init.AutoReloadPreload = TIM_AUTORELOAD_PRELOAD_DISABLE;
  if (HAL_TIM_Base_Init(&htim12) != HAL_OK)
  {
    Error_Handler();
  }
  sClockSourceConfig.ClockSource = TIM_CLOCKSOURCE_INTERNAL;
  if (HAL_TIM_ConfigClockSource(&htim12, &sClockSourceConfig) != HAL_OK)
  {
    Error_Handler();
  }
  if (HAL_TIM_OC_Init(&htim12) != HAL_OK)
  {
    Error_Handler();
  }
  sMasterConfig.MasterOutputTrigger = TIM_TRGO_RESET;
  sMasterConfig.MasterSlaveMode = TIM_MASTERSLAVEMODE_DISABLE;
  if (HAL_TIMEx_MasterConfigSynchronization(&htim12, &sMasterConfig) != HAL_OK)
  {
    Error_Handler();
  }
  sConfigOC.OCMode = TIM_OCMODE_TOGGLE;
  sConfigOC.Pulse = 0;
  sConfigOC.OCPolarity = TIM_OCPOLARITY_HIGH;
  sConfigOC.OCFastMode = TIM_OCFAST_DISABLE;
  if (HAL_TIM_OC_ConfigChannel(&htim12, &sConfigOC, TIM_CHANNEL_1) != HAL_OK)
  {
    Error_Handler();
  }
  HAL_TIM_MspPostInit(&htim12);

}

static void MX_TIM13_Init(void)
{

  TIM_OC_InitTypeDef sConfigOC = {0};

  htim13.Instance = TIM13;
  htim13.Init.Prescaler = 5;
  htim13.Init.CounterMode = TIM_COUNTERMODE_UP;
  htim13.Init.Period = 65535;
  htim13.Init.ClockDivision = TIM_CLOCKDIVISION_DIV1;
  htim13.Init.AutoReloadPreload = TIM_AUTORELOAD_PRELOAD_DISABLE;
  if (HAL_TIM_Base_Init(&htim13) != HAL_OK)
  {
    Error_Handler();
  }
  if (HAL_TIM_OC_Init(&htim13) != HAL_OK)
  {
    Error_Handler();
  }
  sConfigOC.OCMode = TIM_OCMODE_TOGGLE;
  sConfigOC.Pulse = 0;
  sConfigOC.OCPolarity = TIM_OCPOLARITY_HIGH;
  sConfigOC.OCFastMode = TIM_OCFAST_DISABLE;
  if (HAL_TIM_OC_ConfigChannel(&htim13, &sConfigOC, TIM_CHANNEL_1) != HAL_OK)
  {
    Error_Handler();
  }
  HAL_TIM_MspPostInit(&htim13);

}

static void MX_TIM14_Init(void)
{

  TIM_OC_InitTypeDef sConfigOC = {0};

  htim14.Instance = TIM14;
  htim14.Init.Prescaler = 5;
  htim14.Init.CounterMode = TIM_COUNTERMODE_UP;
  htim14.Init.Period = 65535;
  htim14.Init.ClockDivision = TIM_CLOCKDIVISION_DIV1;
  htim14.Init.AutoReloadPreload = TIM_AUTORELOAD_PRELOAD_DISABLE;
  if (HAL_TIM_Base_Init(&htim14) != HAL_OK)
  {
    Error_Handler();
  }
  if (HAL_TIM_OC_Init(&htim14) != HAL_OK)
  {
    Error_Handler();
  }
  sConfigOC.OCMode = TIM_OCMODE_TOGGLE;
  sConfigOC.Pulse = 0;
  sConfigOC.OCPolarity = TIM_OCPOLARITY_HIGH;
  sConfigOC.OCFastMode = TIM_OCFAST_DISABLE;
  if (HAL_TIM_OC_ConfigChannel(&htim14, &sConfigOC, TIM_CHANNEL_1) != HAL_OK)
  {
    Error_Handler();
  }
  HAL_TIM_MspPostInit(&htim14);

}

static void MX_TIM15_Init(void)
{

  TIM_ClockConfigTypeDef sClockSourceConfig = {0};
  TIM_MasterConfigTypeDef sMasterConfig = {0};
  TIM_OC_InitTypeDef sConfigOC = {0};
  TIM_BreakDeadTimeConfigTypeDef sBreakDeadTimeConfig = {0};

  htim15.Instance = TIM15;
  htim15.Init.Prescaler = 5;
  htim15.Init.CounterMode = TIM_COUNTERMODE_UP;
  htim15.Init.Period = 65535;
  htim15.Init.ClockDivision = TIM_CLOCKDIVISION_DIV1;
  htim15.Init.RepetitionCounter = 0;
  htim15.Init.AutoReloadPreload = TIM_AUTORELOAD_PRELOAD_DISABLE;
  if (HAL_TIM_Base_Init(&htim15) != HAL_OK)
  {
    Error_Handler();
  }
  sClockSourceConfig.ClockSource = TIM_CLOCKSOURCE_INTERNAL;
  if (HAL_TIM_ConfigClockSource(&htim15, &sClockSourceConfig) != HAL_OK)
  {
    Error_Handler();
  }
  if (HAL_TIM_OC_Init(&htim15) != HAL_OK)
  {
    Error_Handler();
  }
  sMasterConfig.MasterOutputTrigger = TIM_TRGO_OC2REF;
  sMasterConfig.MasterSlaveMode = TIM_MASTERSLAVEMODE_DISABLE;
  if (HAL_TIMEx_MasterConfigSynchronization(&htim15, &sMasterConfig) != HAL_OK)
  {
    Error_Handler();
  }
  sConfigOC.OCMode = TIM_OCMODE_TOGGLE;
  sConfigOC.Pulse = 0;
  sConfigOC.OCPolarity = TIM_OCPOLARITY_HIGH;
  sConfigOC.OCNPolarity = TIM_OCNPOLARITY_HIGH;
  sConfigOC.OCFastMode = TIM_OCFAST_DISABLE;
  sConfigOC.OCIdleState = TIM_OCIDLESTATE_RESET;
  sConfigOC.OCNIdleState = TIM_OCNIDLESTATE_RESET;
  if (HAL_TIM_OC_ConfigChannel(&htim15, &sConfigOC, TIM_CHANNEL_2) != HAL_OK)
  {
    Error_Handler();
  }
  sBreakDeadTimeConfig.OffStateRunMode = TIM_OSSR_DISABLE;
  sBreakDeadTimeConfig.OffStateIDLEMode = TIM_OSSI_DISABLE;
  sBreakDeadTimeConfig.LockLevel = TIM_LOCKLEVEL_OFF;
  sBreakDeadTimeConfig.DeadTime = 0;
  sBreakDeadTimeConfig.BreakState = TIM_BREAK_DISABLE;
  sBreakDeadTimeConfig.BreakPolarity = TIM_BREAKPOLARITY_HIGH;
  sBreakDeadTimeConfig.BreakFilter = 0;
  sBreakDeadTimeConfig.AutomaticOutput = TIM_AUTOMATICOUTPUT_DISABLE;
  if (HAL_TIMEx_ConfigBreakDeadTime(&htim15, &sBreakDeadTimeConfig) != HAL_OK)
  {
    Error_Handler();
  }
  HAL_TIM_MspPostInit(&htim15);

}

static void MX_TIM16_Init(void)
{

  htim16.Instance = TIM16;
  htim16.Init.Prescaler = 11999;
  htim16.Init.CounterMode = TIM_COUNTERMODE_UP;
  htim16.Init.Period = 65535;
  htim16.Init.ClockDivision = TIM_CLOCKDIVISION_DIV1;
  htim16.Init.RepetitionCounter = 0;
  htim16.Init.AutoReloadPreload = TIM_AUTORELOAD_PRELOAD_DISABLE;
  if (HAL_TIM_Base_Init(&htim16) != HAL_OK)
  {
    Error_Handler();
  }

}

static void MX_TIM17_Init(void)
{

  htim17.Instance = TIM17;
  htim17.Init.Prescaler = 239;
  htim17.Init.CounterMode = TIM_COUNTERMODE_UP;
  htim17.Init.Period = 999;
  htim17.Init.ClockDivision = TIM_CLOCKDIVISION_DIV1;
  htim17.Init.RepetitionCounter = 0;
  htim17.Init.AutoReloadPreload = TIM_AUTORELOAD_PRELOAD_DISABLE;
  if (HAL_TIM_Base_Init(&htim17) != HAL_OK)
  {
    Error_Handler();
  }

}

static void MX_USART2_UART_Init(void)
{

  huart2.Instance = USART2;
  huart2.Init.BaudRate = 460800;
  huart2.Init.WordLength = UART_WORDLENGTH_8B;
  huart2.Init.StopBits = UART_STOPBITS_1;
  huart2.Init.Parity = UART_PARITY_NONE;
  huart2.Init.Mode = UART_MODE_TX_RX;
  huart2.Init.HwFlowCtl = UART_HWCONTROL_NONE;
  huart2.Init.OverSampling = UART_OVERSAMPLING_16;
  huart2.Init.OneBitSampling = UART_ONE_BIT_SAMPLE_DISABLE;
  huart2.Init.ClockPrescaler = UART_PRESCALER_DIV1;
  huart2.AdvancedInit.AdvFeatureInit = UART_ADVFEATURE_NO_INIT;
  if (HAL_UART_Init(&huart2) != HAL_OK)
  {
    Error_Handler();
  }
  if (HAL_UARTEx_SetTxFifoThreshold(&huart2, UART_TXFIFO_THRESHOLD_1_8) != HAL_OK)
  {
    Error_Handler();
  }
  if (HAL_UARTEx_SetRxFifoThreshold(&huart2, UART_RXFIFO_THRESHOLD_1_8) != HAL_OK)
  {
    Error_Handler();
  }
  if (HAL_UARTEx_DisableFifoMode(&huart2) != HAL_OK)
  {
    Error_Handler();
  }

}

static void MX_USART3_UART_Init(void)
{

  huart3.Instance = USART3;
  huart3.Init.BaudRate = 460800;
  huart3.Init.WordLength = UART_WORDLENGTH_8B;
  huart3.Init.StopBits = UART_STOPBITS_1;
  huart3.Init.Parity = UART_PARITY_NONE;
  huart3.Init.Mode = UART_MODE_TX_RX;
  huart3.Init.HwFlowCtl = UART_HWCONTROL_NONE;
  huart3.Init.OverSampling = UART_OVERSAMPLING_16;
  huart3.Init.OneBitSampling = UART_ONE_BIT_SAMPLE_DISABLE;
  huart3.Init.ClockPrescaler = UART_PRESCALER_DIV1;
  huart3.AdvancedInit.AdvFeatureInit = UART_ADVFEATURE_NO_INIT;
  if (HAL_UART_Init(&huart3) != HAL_OK)
  {
    Error_Handler();
  }
  if (HAL_UARTEx_SetTxFifoThreshold(&huart3, UART_TXFIFO_THRESHOLD_1_8) != HAL_OK)
  {
    Error_Handler();
  }
  if (HAL_UARTEx_SetRxFifoThreshold(&huart3, UART_RXFIFO_THRESHOLD_1_8) != HAL_OK)
  {
    Error_Handler();
  }
  if (HAL_UARTEx_DisableFifoMode(&huart3) != HAL_OK)
  {
    Error_Handler();
  }

}

static void MX_DMA_Init(void)
{

  /* DMA controller clock enable */
  __HAL_RCC_DMA1_CLK_ENABLE();

  /* DMA interrupt init */
  /* DMA1_Stream0_IRQn interrupt configuration */
  HAL_NVIC_SetPriority(DMA1_Stream0_IRQn, 0, 0);
  HAL_NVIC_EnableIRQ(DMA1_Stream0_IRQn);

}

static void MX_GPIO_Init(void)
{
  GPIO_InitTypeDef GPIO_InitStruct = {0};

  /* GPIO Ports Clock Enable */
  __HAL_RCC_GPIOE_CLK_ENABLE();
  __HAL_RCC_GPIOH_CLK_ENABLE();
  __HAL_RCC_GPIOA_CLK_ENABLE();
  __HAL_RCC_GPIOC_CLK_ENABLE();
  __HAL_RCC_GPIOB_CLK_ENABLE();
  __HAL_RCC_GPIOD_CLK_ENABLE();

  /*Configure GPIO pin Output Level */
  HAL_GPIO_WritePin(GPIOA, LED1_Pin|LED2_Pin, GPIO_PIN_RESET);

  /*Configure GPIO pin Output Level */
  HAL_GPIO_WritePin(GPIOC, LED3_Pin|LED4_Pin|S2_Direction_Pin, GPIO_PIN_RESET);

  /*Configure GPIO pin Output Level */
  HAL_GPIO_WritePin(LED5_GPIO_Port, LED5_Pin, GPIO_PIN_RESET);

  /*Configure GPIO pin Output Level */
  HAL_GPIO_WritePin(GPIOE, LED6_Pin|LED7_Pin|LED8_Pin|LED9_Pin
                          |S4_Enable_Pin|S4_Direction_Pin|EEPROM_WP_Pin, GPIO_PIN_RESET);

  /*Configure GPIO pin Output Level */
  HAL_GPIO_WritePin(GPIOD, S3_Enable_Pin|S3_Direction_Pin|S2_Enable_Pin|S1_Direction_Pin
                          |S1_Enable_Pin, GPIO_PIN_RESET);

  /*Configure GPIO pins : Config_0_Pin Config_1_Pin Config_2_Pin Config_3_Pin */
  GPIO_InitStruct.Pin = Config_0_Pin|Config_1_Pin|Config_2_Pin|Config_3_Pin;
  GPIO_InitStruct.Mode = GPIO_MODE_INPUT;
  GPIO_InitStruct.Pull = GPIO_NOPULL;
  HAL_GPIO_Init(GPIOE, &GPIO_InitStruct);

  /*Configure GPIO pins : LED1_Pin LED2_Pin */
  GPIO_InitStruct.Pin = LED1_Pin|LED2_Pin;
  GPIO_InitStruct.Mode = GPIO_MODE_OUTPUT_PP;
  GPIO_InitStruct.Pull = GPIO_NOPULL;
  GPIO_InitStruct.Speed = GPIO_SPEED_FREQ_LOW;
  HAL_GPIO_Init(GPIOA, &GPIO_InitStruct);

  /*Configure GPIO pins : UI_Sw_Pin S2_Ready_Pin */
  GPIO_InitStruct.Pin = UI_Sw_Pin|S2_Ready_Pin;
  GPIO_InitStruct.Mode = GPIO_MODE_IT_RISING;
  GPIO_InitStruct.Pull = GPIO_NOPULL;
  HAL_GPIO_Init(GPIOA, &GPIO_InitStruct);

  /*Configure GPIO pins : LED3_Pin LED4_Pin S2_Direction_Pin */
  GPIO_InitStruct.Pin = LED3_Pin|LED4_Pin|S2_Direction_Pin;
  GPIO_InitStruct.Mode = GPIO_MODE_OUTPUT_PP;
  GPIO_InitStruct.Pull = GPIO_NOPULL;
  GPIO_InitStruct.Speed = GPIO_SPEED_FREQ_LOW;
  HAL_GPIO_Init(GPIOC, &GPIO_InitStruct);

  /*Configure GPIO pin : LED5_Pin */
  GPIO_InitStruct.Pin = LED5_Pin;
  GPIO_InitStruct.Mode = GPIO_MODE_OUTPUT_PP;
  GPIO_InitStruct.Pull = GPIO_NOPULL;
  GPIO_InitStruct.Speed = GPIO_SPEED_FREQ_LOW;
  HAL_GPIO_Init(LED5_GPIO_Port, &GPIO_InitStruct);

  /*Configure GPIO pins : BTN_A_Pin BTN_B_Pin S4_EncZ_Pin S3_Ready_Pin */
  GPIO_InitStruct.Pin = BTN_A_Pin|BTN_B_Pin|S4_EncZ_Pin|S3_Ready_Pin;
  GPIO_InitStruct.Mode = GPIO_MODE_IT_RISING;
  GPIO_InitStruct.Pull = GPIO_NOPULL;
  HAL_GPIO_Init(GPIOB, &GPIO_InitStruct);

  /*Configure GPIO pin : S4_Ready_Pin */
  GPIO_InitStruct.Pin = S4_Ready_Pin;
  GPIO_InitStruct.Mode = GPIO_MODE_IT_RISING;
  GPIO_InitStruct.Pull = GPIO_NOPULL;
  HAL_GPIO_Init(S4_Ready_GPIO_Port, &GPIO_InitStruct);

  /*Configure GPIO pins : LED6_Pin LED7_Pin LED8_Pin LED9_Pin
                           S4_Enable_Pin S4_Direction_Pin EEPROM_WP_Pin */
  GPIO_InitStruct.Pin = LED6_Pin|LED7_Pin|LED8_Pin|LED9_Pin
                          |S4_Enable_Pin|S4_Direction_Pin|EEPROM_WP_Pin;
  GPIO_InitStruct.Mode = GPIO_MODE_OUTPUT_PP;
  GPIO_InitStruct.Pull = GPIO_NOPULL;
  GPIO_InitStruct.Speed = GPIO_SPEED_FREQ_LOW;
  HAL_GPIO_Init(GPIOE, &GPIO_InitStruct);

  /*Configure GPIO pin : S4_Treach_Pin */
  GPIO_InitStruct.Pin = S4_Treach_Pin;
  GPIO_InitStruct.Mode = GPIO_MODE_IT_FALLING;
  GPIO_InitStruct.Pull = GPIO_NOPULL;
  HAL_GPIO_Init(S4_Treach_GPIO_Port, &GPIO_InitStruct);

  /*Configure GPIO pins : S3_Enable_Pin S3_Direction_Pin S2_Enable_Pin S1_Direction_Pin
                           S1_Enable_Pin */
  GPIO_InitStruct.Pin = S3_Enable_Pin|S3_Direction_Pin|S2_Enable_Pin|S1_Direction_Pin
                          |S1_Enable_Pin;
  GPIO_InitStruct.Mode = GPIO_MODE_OUTPUT_PP;
  GPIO_InitStruct.Pull = GPIO_NOPULL;
  GPIO_InitStruct.Speed = GPIO_SPEED_FREQ_LOW;
  HAL_GPIO_Init(GPIOD, &GPIO_InitStruct);

  /*Configure GPIO pins : S3_Treach_Pin S1_Treach_Pin */
  GPIO_InitStruct.Pin = S3_Treach_Pin|S1_Treach_Pin;
  GPIO_InitStruct.Mode = GPIO_MODE_IT_FALLING;
  GPIO_InitStruct.Pull = GPIO_NOPULL;
  HAL_GPIO_Init(GPIOD, &GPIO_InitStruct);

  /*Configure GPIO pins : S3_EncZ_Pin S1_EncZ_Pin S1_Ready_Pin */
  GPIO_InitStruct.Pin = S3_EncZ_Pin|S1_EncZ_Pin|S1_Ready_Pin;
  GPIO_InitStruct.Mode = GPIO_MODE_IT_RISING;
  GPIO_InitStruct.Pull = GPIO_NOPULL;
  HAL_GPIO_Init(GPIOD, &GPIO_InitStruct);

  /*Configure GPIO pin : S2_Treach_Pin */
  GPIO_InitStruct.Pin = S2_Treach_Pin;
  GPIO_InitStruct.Mode = GPIO_MODE_IT_FALLING;
  GPIO_InitStruct.Pull = GPIO_NOPULL;
  HAL_GPIO_Init(S2_Treach_GPIO_Port, &GPIO_InitStruct);

  /*Configure GPIO pin : S2_EncZ_Pin */
  GPIO_InitStruct.Pin = S2_EncZ_Pin;
  GPIO_InitStruct.Mode = GPIO_MODE_IT_RISING;
  GPIO_InitStruct.Pull = GPIO_NOPULL;
  HAL_GPIO_Init(S2_EncZ_GPIO_Port, &GPIO_InitStruct);

  /* EXTI interrupt init*/
  HAL_NVIC_SetPriority(S1_EncZ_EXTI_IRQn, 1, 0);
  HAL_NVIC_EnableIRQ(S1_EncZ_EXTI_IRQn);

  HAL_NVIC_SetPriority(BTN_A_EXTI_IRQn, 1, 0);
  HAL_NVIC_EnableIRQ(BTN_A_EXTI_IRQn);

  HAL_NVIC_SetPriority(BTN_B_EXTI_IRQn, 1, 0);
  HAL_NVIC_EnableIRQ(BTN_B_EXTI_IRQn);

  HAL_NVIC_SetPriority(S1_Treach_EXTI_IRQn, 1, 0);
  HAL_NVIC_EnableIRQ(S1_Treach_EXTI_IRQn);

  HAL_NVIC_SetPriority(S1_Ready_EXTI_IRQn, 1, 0);
  HAL_NVIC_EnableIRQ(S1_Ready_EXTI_IRQn);

  HAL_NVIC_SetPriority(UI_Sw_EXTI_IRQn, 1, 0);
  HAL_NVIC_EnableIRQ(UI_Sw_EXTI_IRQn);

  HAL_NVIC_SetPriority(S3_Treach_EXTI_IRQn, 1, 0);
  HAL_NVIC_EnableIRQ(S3_Treach_EXTI_IRQn);

}

 /* MPU Configuration */

void MPU_Config(void)
{
  MPU_Region_InitTypeDef MPU_InitStruct = {0};

  /* Disables the MPU */
  HAL_MPU_Disable();

  /** Initializes and configures the Region and the memory to be protected
  */
  MPU_InitStruct.Enable = MPU_REGION_ENABLE;
  MPU_InitStruct.Number = MPU_REGION_NUMBER0;
  MPU_InitStruct.BaseAddress = 0x0;
  MPU_InitStruct.Size = MPU_REGION_SIZE_4GB;
  MPU_InitStruct.SubRegionDisable = 0x87;
  MPU_InitStruct.TypeExtField = MPU_TEX_LEVEL0;
  MPU_InitStruct.AccessPermission = MPU_REGION_NO_ACCESS;
  MPU_InitStruct.DisableExec = MPU_INSTRUCTION_ACCESS_DISABLE;
  MPU_InitStruct.IsShareable = MPU_ACCESS_SHAREABLE;
  MPU_InitStruct.IsCacheable = MPU_ACCESS_NOT_CACHEABLE;
  MPU_InitStruct.IsBufferable = MPU_ACCESS_NOT_BUFFERABLE;

  HAL_MPU_ConfigRegion(&MPU_InitStruct);
  /* Enables the MPU */
  HAL_MPU_Enable(MPU_PRIVILEGED_DEFAULT);

}

void Error_Handler(void)
{
  __disable_irq();
  while (1)
  {
  }
}
